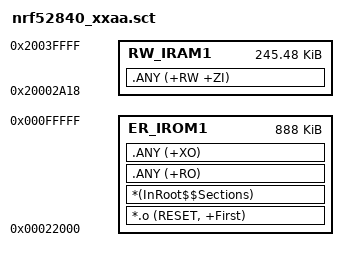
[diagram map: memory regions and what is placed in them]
; *************************************************************
; *** Scatter-Loading Description File generated by uVision ***
; *************************************************************

LR_IROM1 0x00022000 0x000DE000  {    ; load region size_region
  ER_IROM1 0x00022000 0x000DE000  {  ; load address = execution address
   *.o (RESET, +First)
   *(InRoot$$Sections)
   .ANY (+RO)
   .ANY (+XO)
  }
  RW_IRAM1 0x20002A18 0x0003D5E8  {  ; RW data
   .ANY (+RW +ZI)
  }
}

